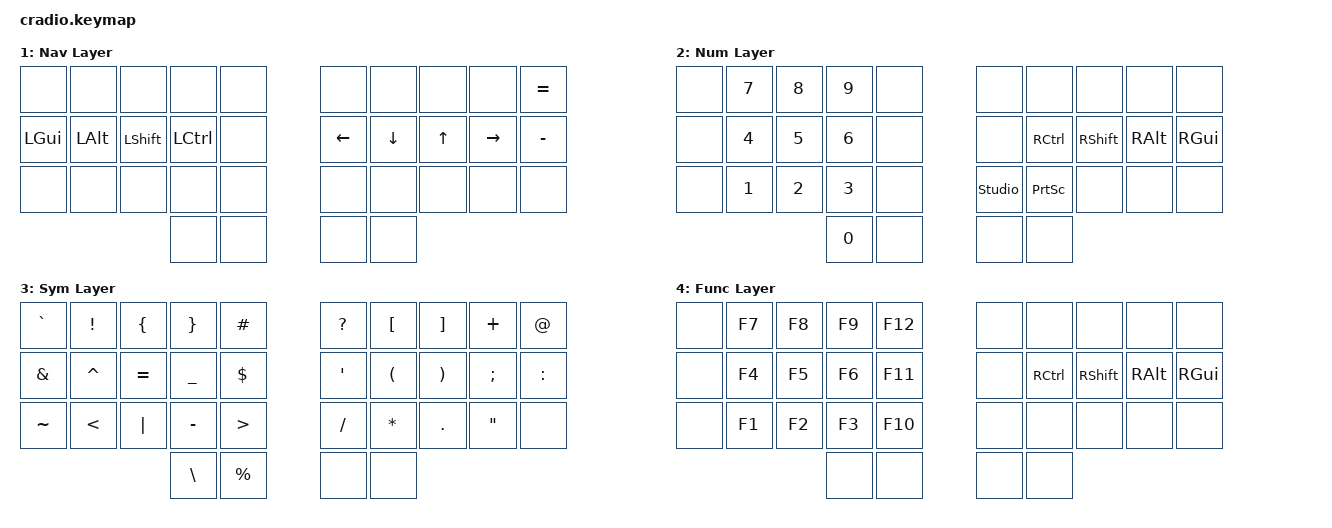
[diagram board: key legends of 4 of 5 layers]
// Copyright (c) 2022 The ZMK Contributors
// SPDX-License-Identifier: MIT

#include <behaviors.dtsi>
#include <dt-bindings/zmk/keys.h>
#include <dt-bindings/zmk/bt.h>

#define HRML(k1,k2,k3,k4) &hml LGUI k1  &hml LALT k2  &hml LSHFT k3  &hml LCTRL k4
#define HRMR(k1,k2,k3,k4) &hmr RCTRL k1  &hmr RSHFT k2  &hmr RALT k3  &hmr RGUI k4

#define KEYS_L 0 1 2 3 4 10 11 12 13 14 20 21 22 23 24
#define KEYS_R 5 6 7 8 9 15 16 17 18 19 25 26 27 28 29
#define THUMBS 30 31 32 33

/ {
    behaviors {
        hml: home_row_mod_left {
            compatible = "zmk,behavior-hold-tap";
            #binding-cells = <2>;
            flavor = "balanced";
            tapping-term-ms = <280>;
            quick-tap-ms = <175>;
            require-prior-idle-ms = <150>;
            hold-trigger-key-positions = <KEYS_R THUMBS>;
            hold-trigger-on-release;
            bindings = <&kp>, <&kp>;
        };

        hmr: home_row_mod_right {
            compatible = "zmk,behavior-hold-tap";
            #binding-cells = <2>;
            flavor = "balanced";
            tapping-term-ms = <280>;
            quick-tap-ms = <175>;
            require-prior-idle-ms = <150>;
            hold-trigger-key-positions = <KEYS_L THUMBS>;
            hold-trigger-on-release;
            bindings = <&kp>, <&kp>;
        };
    };

    keymap {
        compatible = "zmk,keymap";
        default_layer {
            display-name = "Default Layer";
            bindings = <
        //╭──────────┬──────────┬──────────┬──────────┬──────────╮   ╭──────────┬──────────┬──────────┬──────────┬──────────╮
        //│  B       │  L       │  D       │  C       │  V       │   │  J       │  F       │  O       │  U       │  , <     │
            &kp B      &kp L      &kp D      &kp C      &kp V          &kp J      &kp F      &kp O      &kp U      &kp COMMA
        //├──────────┼──────────┼──────────┼──────────┼──────────┤   ├──────────┼──────────┼──────────┼──────────┼──────────┤
        //│  N       │  R       │  T       │  S       │  G       │   │  Y       │  H       │  A       │  E       │  I       │
            HRML(N,        R,         T,         S)     &kp G          &kp Y      HRMR(H,        A,         E,        I)
        //├──────────┼──────────┼──────────┼──────────┼──────────┤   ├──────────┼──────────┼──────────┼──────────┼──────────┤
        //│  X       │  Q       │  M       │  W       │  Z       │   │  K       │  P       │ Esc      │ Enter    │  Del     │
            &kp X      &kp Q      &kp M      &kp W      &kp Z          &kp K      &kp P      &kp ESC    &kp ENTER  &lt 4 DEL
        //╰──────────┴──────────┴──────────┼──────────┼──────────┤   ├──────────┼──────────┼──────────┴──────────┴──────────╯
                                            &lt 1 SPACE &mt LSFT TAB  &mo 3      &lt 2 BSPC
        //                                 ╰──────────┴──────────╯   ╰──────────┴──────────╯
            >;
        };

        nav_layer {
            display-name = "Nav Layer";
            bindings = <
        //╭──────────┬──────────┬──────────┬──────────┬──────────╮   ╭──────────┬──────────┬──────────┬──────────┬──────────╮
        //│          │          │          │          │          │   │          │          │          │          │  =       │
            &none      &none      &none      &none      &none         &none      &none      &none      &none      &kp EQUAL
        //├──────────┼──────────┼──────────┼──────────┼──────────┤   ├──────────┼──────────┼──────────┼──────────┼──────────┤
        //│ Gui      │  Alt     │  Shift   │  Ctrl    │          │   │ LEFT     │ DOWN     │ UP       │ RIGHT    │  -       │
            &kp LGUI   &kp LALT   &kp LSHFT &kp LCTRL   &none         &kp LEFT   &kp DOWN   &kp UP     &kp RIGHT  &kp MINUS
        //├──────────┼──────────┼──────────┼──────────┼──────────┤   ├──────────┼──────────┼──────────┼──────────┼──────────┤
        //│          │          │          │          │          │   │          │          │          │          │          │
           &none      &none      &none      &none      &none          &none      &none      &none      &none      &none
        //╰──────────┴──────────┴──────────┼──────────┼──────────┤   ├──────────┼──────────┼──────────┴──────────┴──────────╯
                                             &none     &none           &none     &none
        //                                 ╰──────────┴──────────╯   ╰──────────┴──────────╯
            >;
        };

        num_layer {
            display-name = "Num Layer";
            bindings = <
        //╭──────────┬──────────┬──────────┬──────────┬──────────╮   ╭──────────┬──────────┬──────────┬──────────┬──────────╮
        //│          │  7       │  8       │  9       │          │   │          │          │          │          │          │
            &none     &kp N7     &kp N8     &kp N9     &none          &none      &none      &none      &none      &none
        //├──────────┼──────────┼──────────┼──────────┼──────────┤   ├──────────┼──────────┼──────────┼──────────┼──────────┤
        //│          │  4       │  5       │  6       │          │   │          │  Ctrl    │  Shift   │  Alt     │  Gui     │
            &none     &kp N4     &kp N5     &kp N6     &none          &none      &kp RCTRL  &kp RSHFT  &kp RALT   &kp RGUI    
        //├──────────┼──────────┼──────────┼──────────┼──────────┤   ├──────────┼──────────┼──────────┼──────────┼──────────┤
        //│          │  1       │  2       │  3       │          │   │          │ PrintScr │          │          │          │
            &none     &kp N1     &kp N2     &kp N3     &none          &studio_unlock &kp PSCRN  &none      &none      &none
        //╰──────────┴──────────┴──────────┼──────────┼──────────┤   ├──────────┼──────────┼──────────┴──────────┴──────────╯
                                             &kp N0    &none          &none      &none
        //                                 ╰──────────┴──────────╯   ╰──────────┴──────────╯
            >;
        };

        sym_layer {
            display-name = "Sym Layer";
            bindings = <
        //╭──────────┬──────────┬──────────┬──────────┬──────────╮   ╭──────────┬──────────┬──────────┬──────────┬──────────╮
        //│ `        │  !       │  {       │  }       │  #       │   │  ?       │  [       │  ]       │ +        │  @       │
           &kp GRAVE  &kp EXCL   &kp LBRC   &kp RBRC   &kp HASH       &kp QMARK  &kp LBKT   &kp RBKT   &kp PLUS   &kp AT
        //├──────────┼──────────┼──────────┼──────────┼──────────┤   ├──────────┼──────────┼──────────┼──────────┼──────────┤
        //│ &        │  ^       │  =       │  _       │  $       │   │  '       │  (       │  )       │ ;        │  :       │
            &kp AMPS  &kp CARET  &kp EQUAL  &kp UNDER  &kp DLLR       &kp APOS   &kp LPAR   &kp RPAR   &kp SEMI   &kp COLON
        //├──────────┼──────────┼──────────┼──────────┼──────────┤   ├──────────┼──────────┼──────────┼──────────┼──────────┤
        //│ ~        │  <       │  |       │ -        │ >        │   │  /       │  *       │  .       │ "        │          │
            &kp TILDE &kp LT     &kp PIPE   &kp MINUS  &kp GT         &kp FSLH   &kp STAR   &kp DOT     &kp DQT     &none
        //╰──────────┴──────────┴──────────┼──────────┼──────────┤   ├──────────┼──────────┼──────────┴──────────┴──────────╯
                                             &kp BSLH   &kp PRCNT      &none     &none
        //                                 ╰──────────┴──────────╯   ╰──────────┴──────────╯
            >;
        };

        func_layer {
            display-name = "Func Layer";
            bindings = <
        //╭──────────┬──────────┬──────────┬──────────┬──────────╮   ╭──────────┬──────────┬──────────┬──────────┬──────────╮
        //│          │  F7      │  F8      │  F9      │ F12      │   │          │          │          │          │          │
            &none     &kp F7     &kp F8     &kp F9     &kp F12        &none      &none      &none      &none      &none
        //├──────────┼──────────┼──────────┼──────────┼──────────┤   ├──────────┼──────────┼──────────┼──────────┼──────────┤
        //│          │  F4      │  F5      │  F6      │          │   │          │  Ctrl    │  Shift   │  Alt     │  Gui     │
            &none     &kp F4     &kp F5     &kp F6     &kp F11        &none      &kp RCTRL  &kp RSHFT  &kp RALT   &kp RGUI    
        //├──────────┼──────────┼──────────┼──────────┼──────────┤   ├──────────┼──────────┼──────────┼──────────┼──────────┤
        //│          │  F1      │  F2      │  F3      │ F10      │   │          │          │          │          │          │
            &none     &kp F1     &kp F2     &kp F3     &kp F10        &none      &none      &none      &none      &none
        //╰──────────┴──────────┴──────────┼──────────┼──────────┤   ├──────────┼──────────┼──────────┴──────────┴──────────╯
                                             &none     &none          &none      &none
        //                                 ╰──────────┴──────────╯   ╰──────────┴──────────╯
            >;
        };
    };
};
